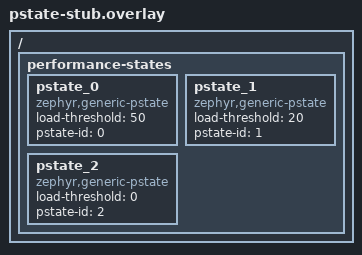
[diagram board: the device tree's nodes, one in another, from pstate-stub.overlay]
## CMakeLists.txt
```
# Copyright (c) 2025 Analog Devices, Inc.
#
# SPDX-License-Identifier: Apache-2.0

cmake_minimum_required(VERSION 3.28.0)

find_package(Zephyr REQUIRED HINTS $ENV{ZEPHYR_BASE})
project(cpu_freq_on_demand_sample)

target_sources(app PRIVATE src/main.c)
```

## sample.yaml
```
sample:
  description: CPU frequency scaling on-demand policy sample
  name: CPU Freq On-demand Sample
common:
  tags: cpu_freq
  harness: console
  harness_config:
    type: multi_line
    regex:
      - "^.*<inf> cpu_freq_on_demand_sample: Starting CPU Freq on-demand policy Sample!"
      - "^.*<dbg> cpu_load_metric.cpu_load_metric_get: CPU[0-9]+ Execution cycles: \
         [0-9]+, Total cycles: [0-9]+"
      - "^.*<dbg> cpu_freq_policy_on_demand.cpu_freq_policy_select_pstate: \
         CPU[0-9]+ Load: [0-9]+%"
      - "^.*<dbg> cpu_freq_policy_on_demand.cpu_freq_policy_select_pstate: On-Demand Policy: \
         Selected P-state [0-9]+ with load_threshold=[0-9]+%"

tests:
  sample.cpu_freq.soc:
    integration_platforms:
      - native_sim
      - native_sim/native/64
    platform_allow:
      - native_sim
      - native_sim/native/64

  sample.cpu_freq.stub:
    integration_platforms:
      - qemu_cortex_a53/qemu_cortex_a53/smp
      - qemu_x86
    platform_allow:
      - qemu_cortex_a53/qemu_cortex_a53/smp
      - qemu_x86
    extra_dtc_overlay_files:
      - pstate-stub.overlay
    extra_configs:
      - CONFIG_CPU_FREQ_PSTATE_SET_STUB=y
```

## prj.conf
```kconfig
# Copyright (c) 2025 Analog Devices, Inc.
#
# SPDX-License-Identifier: Apache-2.0

CONFIG_LOG=y

# CPU Frequency Subsystem Configuration
CONFIG_CPU_FREQ=y
CONFIG_CPU_FREQ_LOG_LEVEL_DBG=y
CONFIG_CPU_LOAD_METRIC_LOG_LEVEL_DBG=y
CONFIG_CPU_FREQ_POLICY_ON_DEMAND=y
CONFIG_CPU_FREQ_INTERVAL_MS=500
```

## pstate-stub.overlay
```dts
/ {
	performance-states {
		pstate_0: pstate_0 {
			compatible = "zephyr,generic-pstate";
			load-threshold = <50>;
			pstate-id = <0>;
		};
		pstate_1: pstate_1 {
			compatible = "zephyr,generic-pstate";
			load-threshold = <20>;
			pstate-id = <1>;
		};
		pstate_2: pstate_2 {
			compatible = "zephyr,generic-pstate";
			load-threshold = <0>;
			pstate-id = <2>;
		};
	};
};
```

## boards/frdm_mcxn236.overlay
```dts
/*
 * Copyright 2025 NXP
 *
 * SPDX-License-Identifier: Apache-2.0
 */

&os_timer {
	status = "okay";
};

&systick {
	status = "disabled";
};
```

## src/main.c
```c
/*
 * Copyright (c) 2025 Analog Devices, Inc.
 *
 * SPDX-License-Identifier: Apache-2.0
 */

#include <stdio.h>
#include <zephyr/kernel.h>
#include <zephyr/logging/log.h>

LOG_MODULE_REGISTER(cpu_freq_on_demand_sample, LOG_LEVEL_INF);

#define MS_TO_US(x)      ((x) * 1000)
#define PERCENT_SLEEP_MS (CONFIG_CPU_FREQ_INTERVAL_MS / 100)

typedef enum {
	CPU_SCENARIO_0,
	CPU_SCENARIO_1,
	CPU_SCENARIO_2,
	CPU_SCENARIO_3,
	CPU_SCENARIO_4,
	CPU_SCENARIO_COUNT
} cpu_scenario_t;

static int curr_work_time_ms;
static cpu_scenario_t cpu_scenario = CPU_SCENARIO_0;

static void update_sleep_time(struct k_timer *timer_id)
{
	cpu_scenario = (cpu_scenario + 1) % CPU_SCENARIO_COUNT;

	switch (cpu_scenario) {
	case CPU_SCENARIO_0:
		/* CPU is always in sleep */
		curr_work_time_ms = 0;
		break;
	case CPU_SCENARIO_1:
		/* CPU doing some intermittent processing */
		curr_work_time_ms = PERCENT_SLEEP_MS * 10;
		break;
	case CPU_SCENARIO_2:
		/* CPU doing some more intense processing */
		curr_work_time_ms = PERCENT_SLEEP_MS * 25;
		break;
	case CPU_SCENARIO_3:
		/* CPU doing some more intense processing */
		curr_work_time_ms = PERCENT_SLEEP_MS * 50;
		break;
	case CPU_SCENARIO_4:
		/* CPU doing lots of calculations */
		curr_work_time_ms = PERCENT_SLEEP_MS * 100;
		break;
	default:
		LOG_ERR("Unknown CPU scenario: %d", cpu_scenario);
	}
}

K_TIMER_DEFINE(timer, update_sleep_time, NULL);

int main(void)
{
	LOG_INF("Starting CPU Freq on-demand policy Sample!");

	curr_work_time_ms = 0;

	/* Set timer to change cpu scenario periodically */
	k_timer_start(&timer, K_MSEC(CONFIG_CPU_FREQ_INTERVAL_MS),
		      K_MSEC(CONFIG_CPU_FREQ_INTERVAL_MS));

	while (1) {
		k_busy_wait(MS_TO_US(curr_work_time_ms));
		k_msleep(CONFIG_CPU_FREQ_INTERVAL_MS - curr_work_time_ms);
	}
}
```
